# ESP32S31_RADIO register map
Vendor: Espressif; Series: ESP32-S31; File version: 3.52
Registers are 32-bit, read-write, no defined reset value unless marked. A register's access mark holds for its fields unless they carry their own. Offsets are from the block's base; [hi:lo] are bit positions.

## WIFI_MAC_COEX_RUNTIME — Runtime receive-beacon and individual-TWT COEX/PTI words recovered from five complete hal_coex.o leaves. Register addresses, masks and RMW order are exact; fields whose electrical meaning is not established retain UNKNOWN names.
Base 0x2010D89C
0x00 CLEAR_REQUEST — Project-assigned name. Complete hal_clear_rx_beacon_pti sets bit zero through a fresh-read RMW. Complete hal_clr_itwt_pti sets the input-selected bit through the same word; the accepted index domain and remaining bit identities are not inferred.
  [31:0] BITS_0_31_OPAQUE — Opaque: meaning not established.
0x04 RX_BEACON_TIME_HIGH — Project-assigned name. Complete hal_set_rx_beacon_time replaces the low byte from bits 15:8 of its second argument after updating WIFI_MAC_RTC_TIMER_UPDATE.RX_BEACON_TIME_LOW.
  [7:0] VALUE — Project-assigned name.
0x08 ITWT_CONTROL — Project-assigned name. Complete hal_set_itwt_pti clears the low byte and then writes seqz(argument zero) into bit zero. The remaining low-byte semantics are unknown.
  [7:0] BITS_0_7_OPAQUE — Opaque: meaning not established.
0x0C SHARED_RX_PTI — Project-assigned name. Shared receive PTI word updated from the second argument by complete hal_set_rx_beacon_pti and hal_set_itwt_pti. Both leaves preserve bits 31:4 and replace only bits 3:0.
  [3:0] PTI — Project-assigned name.
0x10 RX_BEACON_PTI — Project-assigned name. Complete hal_set_rx_beacon_pti replaces bits 15:12 from the low nibble of its first argument.
  [15:12] PTI — Project-assigned name.

## WIFI_MAC_COLD_HANDSHAKE — Cold MAC initialization request/ready handshake and the adjacent two WDEV timer targets recovered from complete ROM leaves.
Base 0x20104DE0
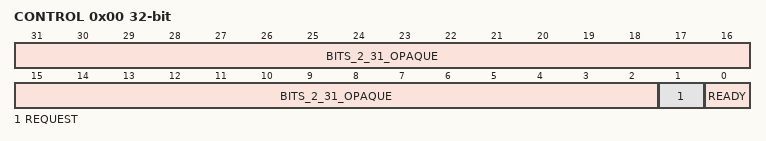
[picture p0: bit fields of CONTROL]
0x00 CONTROL — Project-assigned name. Software sets REQUEST with a fresh-read RMW, then polls READY before touching the remaining MAC state.
  [31:2] BITS_2_31_OPAQUE — Opaque: meaning not established.
  [1] REQUEST — Project-assigned name. Set before the READY polling loop.
  [0] READY ro — Project-assigned name. Polled until asserted after REQUEST.
0x10 WDEV_TIMER_TARGET_0_CONTROL — Project-assigned name. libpp[hal_tsf.o]::hal_wdev_timer_target_enable selects timer zero with argument zero and replaces enable bit zero.
  [0] ENABLE — Project-assigned name.
0x14 WDEV_TIMER_TARGET_0_VALUE wo — Project-assigned name. libpp[hal_tsf.o]::hal_wdev_timer_set_target selects timer zero with argument zero and writes the supplied 32-bit target.
  [31:0] VALUE — Project-assigned name.
0x18 WDEV_TIMER_TARGET_1_CONTROL — Project-assigned name. libpp[hal_tsf.o]::hal_wdev_timer_target_enable selects timer one with argument one and replaces enable bit zero.
  [0] ENABLE — Project-assigned name.
0x1C WDEV_TIMER_TARGET_1_VALUE wo — Project-assigned name. libpp[hal_tsf.o]::hal_wdev_timer_set_target selects timer one with argument one and writes the supplied 32-bit target.
  [31:0] VALUE — Project-assigned name.

## WIFI_MAC_RX_DMA — Descriptor-walker registers recovered from complete rev0 ROM leaves and qualified with the open driver's rotating 32-entry RX ring.
Base 0x20104000
0x7C WORD_007C_OPAQUE — Opaque: meaning not established. Complete mac_rxbuf_init clears the low byte immediately before publishing the descriptor base. Individual bit meanings are unknown.
  [7:0] BITS_0_7_OPAQUE — Opaque: meaning not established.
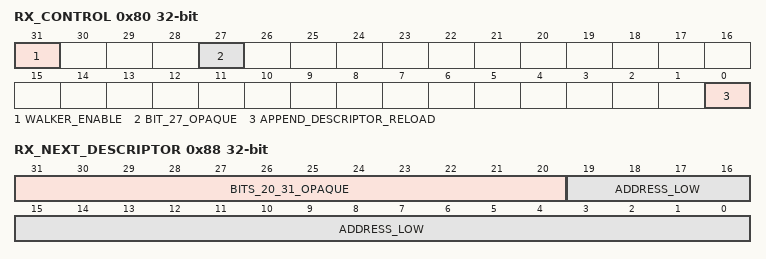
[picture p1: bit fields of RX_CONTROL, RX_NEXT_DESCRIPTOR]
0x80 RX_CONTROL — Project-assigned name. RX descriptor-walker gate, hardware-beacon reload selection and live-list append doorbell.
  [31] WALKER_ENABLE — Project-assigned name. Set by libpp[hal_mac.o]::hal_mac_rx_enable and cleared by libpp[hal_mac.o]::hal_mac_rx_disable; gates the RX descriptor walker.
  [27] BIT_27_OPAQUE — Opaque: meaning not established. Complete hal_mac_set_rxbuf_reload_use_hw_beacon_enable sets bit 27 through one fresh-read RMW.
  [0] APPEND_DESCRIPTOR_RELOAD write-clears — Project-assigned name. Write one after publishing old_tail.next to make a prepared live-list append visible. Hardware clears the bit after accepting the append.
0x84 RX_DESCRIPTOR_BASE — Project-assigned name. Complete first-descriptor address. The ROM and blob leaves publish the unmasked 32-bit pointer when installing a cold or repaired frontier; the selected high-address window separately completes the hardware last/next descriptor observations.
  [31:0] ADDRESS — Project-assigned name.
0x88 RX_NEXT_DESCRIPTOR ro — Project-assigned name. Complete hardware current/next descriptor word. The low 20 bits are the reviewed address projection; meanings of bits 31:20 remain unknown. Complete ROM rom[]::wDev_AppendRxBlocks compares the entire 32-bit word with zero after reload completion, not only ADDRESS_LOW, before it may read LAST and repair RX_DESCRIPTOR_BASE.
  [31:20] BITS_20_31_OPAQUE — Opaque: meaning not established. Unassigned upper state retained by the complete-word zero predicate in rom[]::wDev_AppendRxBlocks. This is deliberately exposed separately from ADDRESS_LOW so production code never reconstructs or masks a register image.
  [19:0] ADDRESS_LOW — Project-assigned name.
0x8C RX_LAST_DESCRIPTOR ro — Project-assigned name. Low 20 bits of the last descriptor accepted by the RX walker.
  [19:0] ADDRESS_LOW — Project-assigned name.
0xC68 WORD_0C68_OPAQUE — Opaque: meaning not established. Complete mac_rxbuf_init sets the low twenty bits before descriptor publication.
  [19:0] BITS_0_19_OPAQUE — Opaque: meaning not established.
0xC6C WORD_0C6C_OPAQUE — Opaque: meaning not established. Complete mac_rxbuf_init replaces the low twenty bits with four before selecting the descriptor high window.
  [19:0] BITS_0_19_OPAQUE — Opaque: meaning not established.
0xC70 RX_DESCRIPTOR_HIGH_WINDOW — Project-assigned name. High 12 descriptor-address bits shared with the low-address RX pointer registers. Complete mac_rxbuf_init and the open driver program 0x2f0 for internal SRAM.
  [31:20] ADDRESS_HIGH — Project-assigned name.
